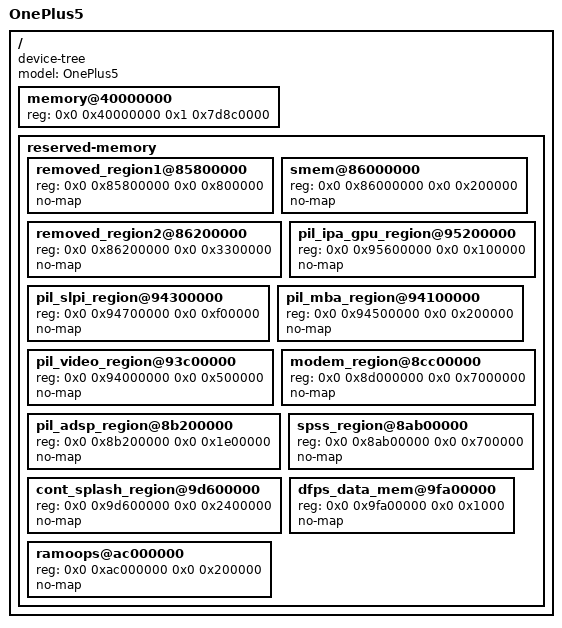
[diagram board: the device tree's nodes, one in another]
/dts-v1/;
/include/ "msm8998.dtsi"
/ {
 model = "OnePlus5"; compatible = "device-tree", "qcom,msm8998";
#address-cells = <2>; #size-cells = <2>;
 memory@40000000 { device_type = "memory"; reg = <0x0 0x40000000 0x1 0x7d8c0000>; };
 reserved-memory { #address-cells = <2>; #size-cells = <2>; ranges;
 removed_region1@85800000 { reg = <0x0 0x85800000 0x0 0x800000>; no-map; };
 smem@86000000 { reg = <0x0 0x86000000 0x0 0x200000>; no-map; };
 removed_region2@86200000 { reg = <0x0 0x86200000 0x0 0x3300000>; no-map; };
 pil_ipa_gpu_region@95200000 { reg = <0x0 0x95600000 0x0 0x100000>; no-map; };
 pil_slpi_region@94300000 { reg = <0x0 0x94700000 0x0 0xf00000>; no-map; };
 pil_mba_region@94100000 { reg = <0x0 0x94500000 0x0 0x200000>; no-map; };
 pil_video_region@93c00000 { reg = <0x0 0x94000000 0x0 0x500000>; no-map; };
 modem_region@8cc00000 { reg = <0x0 0x8d000000 0x0 0x7000000>; no-map; };
 pil_adsp_region@8b200000 { reg = <0x0 0x8b200000 0x0 0x1e00000>; no-map; };
 spss_region@8ab00000 { reg = <0x0 0x8ab00000 0x0 0x700000>; no-map; };
 cont_splash_region@9d600000 { reg = <0x0 0x9d600000 0x0 0x2400000>; no-map; };
 dfps_data_mem@9fa00000 { reg = <0x0 0x9fa00000 0x0 0x1000>; no-map; };
 ramoops@ac000000 { reg = <0x0 0xac000000 0x0 0x200000>; no-map; };
 };
};
